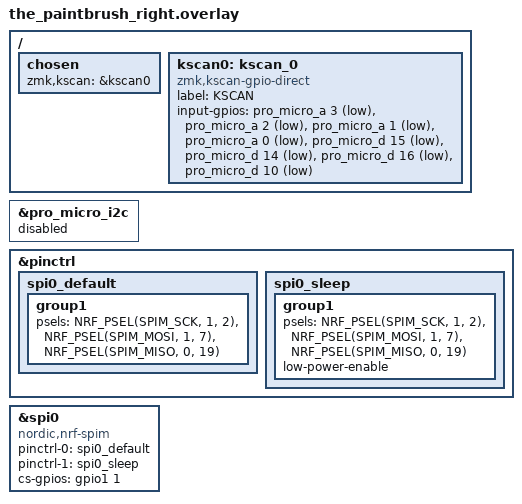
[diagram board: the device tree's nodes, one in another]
/*
 * Copyright (c) 2021 Mike "KemoNine" Crosson
 *
 * SPDX-License-Identifier: MIT
 */

#include <dt-bindings/zmk/matrix_transform.h>

&pro_micro_i2c {
	status = "disabled";
};

/ {
	chosen {
		zmk,kscan = &kscan0;
	};

	kscan0: kscan_0 {
		compatible = "zmk,kscan-gpio-direct";

		label = "KSCAN";

		input-gpios
			= <&pro_micro_a 3 (GPIO_ACTIVE_LOW | GPIO_PULL_UP)>
			, <&pro_micro_a 2 (GPIO_ACTIVE_LOW | GPIO_PULL_UP)>
			, <&pro_micro_a 1 (GPIO_ACTIVE_LOW | GPIO_PULL_UP)>
			, <&pro_micro_a 0 (GPIO_ACTIVE_LOW | GPIO_PULL_UP)>
			, <&pro_micro_d 15 (GPIO_ACTIVE_LOW | GPIO_PULL_UP)>
			, <&pro_micro_d 14 (GPIO_ACTIVE_LOW | GPIO_PULL_UP)>
			, <&pro_micro_d 16 (GPIO_ACTIVE_LOW | GPIO_PULL_UP)>
			, <&pro_micro_d 10 (GPIO_ACTIVE_LOW | GPIO_PULL_UP)>
			;

	};
};

&pinctrl {
    spi0_default: spi0_default {
        group1 {
            psels = <NRF_PSEL(SPIM_SCK, 1, 2)>,
                <NRF_PSEL(SPIM_MOSI, 1, 7)>,
                <NRF_PSEL(SPIM_MISO, 0, 19)>; /* GPIO0 19 is not broken on a nice!nano.*/
        };
    };
    spi0_sleep: spi0_sleep {
        group1 {
            psels = <NRF_PSEL(SPIM_SCK, 1, 2)>,
                <NRF_PSEL(SPIM_MOSI, 1, 7)>,
                <NRF_PSEL(SPIM_MISO, 0, 19)>; /* GPIO0 19 is not broken on a nice!nano.*/
            low-power-enable;
        };
    };
};


nice_view_spi: &spi0 {
    compatible = "nordic,nrf-spim";
    pinctrl-0 = <&spi0_default>;
    pinctrl-1 = <&spi0_sleep>;
    pinctrl-names = "default", "sleep";
    cs-gpios = <&gpio1 1 GPIO_ACTIVE_HIGH>;
};

